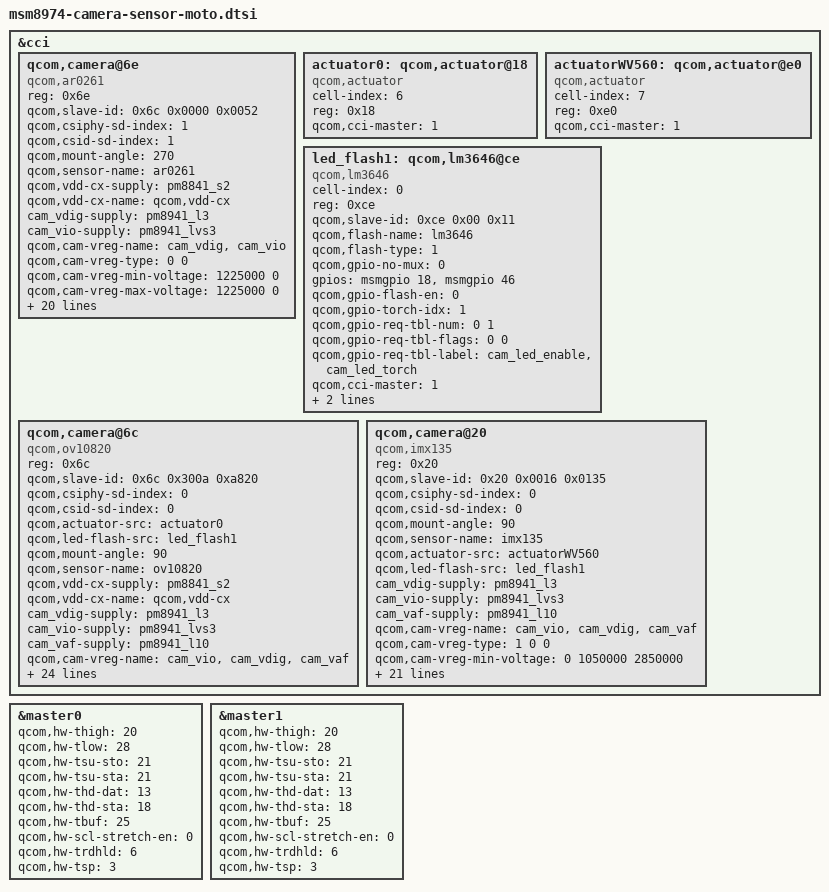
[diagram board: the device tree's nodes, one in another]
/*
 * Copyright (c) 2012-2013, The Linux Foundation. All rights reserved.
 *
 * This program is free software; you can redistribute it and/or modify
 * it under the terms of the GNU General Public License version 2 and
 * only version 2 as published by the Free Software Foundation.
 *
 * This program is distributed in the hope that it will be useful,
 * but WITHOUT ANY WARRANTY; without even the implied warranty of
 * MERCHANTABILITY or FITNESS FOR A PARTICULAR PURPOSE.  See the
 * GNU General Public License for more details.
 */

&cci {

	qcom,camera@6e {
		compatible = "qcom,ar0261";
		reg = <0x6e>;
		qcom,slave-id = <0x6c 0x0000 0x0052>;
		qcom,csiphy-sd-index = <1>;
		qcom,csid-sd-index = <1>;
		qcom,mount-angle = <270>;
		qcom,sensor-name = "ar0261";
		qcom,vdd-cx-supply = <&pm8841_s2>;
		qcom,vdd-cx-name = "qcom,vdd-cx";
		cam_vdig-supply = <&pm8941_l3>;
		cam_vio-supply = <&pm8941_lvs3>;
		qcom,cam-vreg-name = "cam_vdig", "cam_vio";
		qcom,cam-vreg-type = <0 0>;
		qcom,cam-vreg-min-voltage = <1225000 0>;
		qcom,cam-vreg-max-voltage = <1225000 0>;
		qcom,cam-vreg-op-mode = <105000 0>;
		qcom,gpio-no-mux = <0>;
		gpios = <&msmgpio 17 0>,
			<&msmgpio 103 0>,
			<&msmgpio 96 0>,
			<&msmgpio 7 0>;
		qcom,gpio-reset = <1>;
		qcom,gpio-standby = <2>;
		qcom,gpio-pwren = <3>;
		qcom,gpio-req-tbl-num = <0 1 2 3>;
		qcom,gpio-req-tbl-flags = <1 0 0 0>;
		qcom,gpio-req-tbl-label = "CAMIF_MCLK",
					  "CAM_RESET",
					  "CAM_AVDD",
					  "CAM_VDIG";
		qcom,gpio-set-tbl-num = <1 1>;
		qcom,gpio-set-tbl-flags = <0 2>;
		qcom,gpio-set-tbl-delay = <1000 4000>;
		qcom,csi-lane-assign = <0x4320>;
		qcom,csi-lane-mask = <0x07>;
		qcom,sensor-position = <1>;
		qcom,sensor-mode = <1>;
		qcom,sensor-type = <0>;
		qcom,cci-master = <1>;
		status = "ok";
	};

	actuator0: qcom,actuator@18 {
		cell-index = <6>;
		reg = <0x18>;
		compatible = "qcom,actuator";
		qcom,cci-master = <1>;
	};

	actuatorWV560: qcom,actuator@e0 {
		cell-index = <7>;
		reg = <0xe0>;
		compatible = "qcom,actuator";
		qcom,cci-master = <1>;
	};

	led_flash1: qcom,lm3646@ce {
		cell-index = <0>;
		reg = <0xce>;
		qcom,slave-id = <0xce 0x00 0x11>;
		compatible = "qcom,lm3646";
		qcom,flash-name = "lm3646";
		qcom,flash-type = <1>;
		qcom,gpio-no-mux = <0>;
		gpios = <&msmgpio 18 0>,
		        <&msmgpio 46 0>;
		qcom,gpio-flash-en = <0>;
		qcom,gpio-torch-idx = <1>;
		qcom,gpio-req-tbl-num = <0 1>;
		qcom,gpio-req-tbl-flags = <0 0>;
		qcom,gpio-req-tbl-label = "cam_led_enable",
			                  "cam_led_torch";
		qcom,cci-master = <1>;
		flash-en-support = <1>;
		flash-now-support = <0>;
	};

	qcom,camera@6c {
		compatible = "qcom,ov10820";
		reg = <0x6c>;
		qcom,slave-id = <0x6c 0x300a 0xa820>;
		qcom,csiphy-sd-index = <0>;
		qcom,csid-sd-index = <0>;
		qcom,actuator-src = <&actuator0>;
		qcom,led-flash-src = <&led_flash1>;
		qcom,mount-angle = <90>;
		qcom,sensor-name = "ov10820";
		qcom,vdd-cx-supply = <&pm8841_s2>;
		qcom,vdd-cx-name = "qcom,vdd-cx";
		cam_vdig-supply = <&pm8941_l3>;
		cam_vio-supply = <&pm8941_lvs3>;
		cam_vaf-supply = <&pm8941_l10>;
		qcom,cam-vreg-name = "cam_vio", "cam_vdig", "cam_vaf";
		qcom,cam-vreg-type = <0 0 0>;
		qcom,cam-vreg-min-voltage = <0 1225000 2850000>;
		qcom,cam-vreg-max-voltage = <0 1225000 2850000>;
		qcom,cam-vreg-op-mode = <0 105000 0>;
		qcom,gpio-no-mux = <0>;

		gpios = <&msmgpio 19 0>,
			<&msmgpio 89 0>,
			<&msmgpio 15 0>,
			<&pm8941_gpios 13 0>,
			<&pm8941_gpios 25 0>,
			<&pm8941_gpios 7  0>,
			<&msmgpio 91 0>;
		qcom,gpio-reset = <4>;
		qcom,gpio-standby = <1>;
		qcom,gpio-pwren = <3>;
		qcom,gpio-req-tbl-num = <0 1 2 3 4 5 6>;
		qcom,gpio-req-tbl-flags = <0 0 0 0 0 0 0>;
		qcom,gpio-req-tbl-label = "ANA_EN",
					  "PWDN_N",
					  "MCLK",
					  "DVDD_EN",
					  "RST_N",
					  "OV660_RST_N",
					  "DIG_EN";

		qcom,gpio-set-tbl-num = <1 1>;
		qcom,gpio-set-tbl-flags = <0 2>;
		qcom,gpio-set-tbl-delay = <1000 4000>;
		qcom,csi-lane-assign = <0x4320>;
		qcom,csi-lane-mask = <0x1f>;
		qcom,sensor-position = <0>;
		qcom,sensor-mode = <0>;
		qcom,sensor-type = <0>;
		qcom,cci-master = <1>;
		status = "ok";
	};

	qcom,camera@20 {
		compatible = "qcom,imx135";
		reg = <0x20>;
		qcom,slave-id = <0x20 0x0016 0x0135>;
		qcom,csiphy-sd-index = <0>;
		qcom,csid-sd-index = <0>;
		qcom,mount-angle = <90>;
		qcom,sensor-name = "imx135";
		qcom,actuator-src = <&actuatorWV560>;
		qcom,led-flash-src = <&led_flash1>;
		cam_vdig-supply = <&pm8941_l3>;
		cam_vio-supply = <&pm8941_lvs3>;
		cam_vaf-supply = <&pm8941_l10>;
		qcom,cam-vreg-name = "cam_vio", "cam_vdig", "cam_vaf";
		qcom,cam-vreg-type = <1 0 0>;
		qcom,cam-vreg-min-voltage = <0 1050000 2850000>;
		qcom,cam-vreg-max-voltage = <0 1225000 2850000>;
		qcom,cam-vreg-op-mode = <0 1050000 0>;
		qcom,gpio-no-mux = <0>;
		gpios = <&msmgpio 15 0>,
			<&msmgpio 19 0>,
			<&msmgpio 89 0>,
			<&pm8941_gpios 13 0>,
			<&pm8941_gpios 25 0>;
		qcom,gpio-reset = <4>;
		qcom,gpio-vana = <1>;
		qcom,gpio-vdig = <3>;
		qcom,gpio-req-tbl-num = <0 1 2 3 4>;
		qcom,gpio-req-tbl-flags = <0 0 1 0 0>;
		qcom,gpio-req-tbl-label = "MCLK",
					  "ANA_EN",
					  "EEPROM_WP",
					  "DVDD_EN",
					  "CAM_RESET";
		qcom,gpio-set-tbl-num = <1 1>;
		qcom,gpio-set-tbl-flags = <0 2>;
		qcom,gpio-set-tbl-delay = <1000 30000>;
		qcom,csi-lane-assign = <0x4320>;
		qcom,csi-lane-mask = <0x1f>;
		qcom,sensor-position = <0>;
		qcom,sensor-mode = <0>;
		qcom,sensor-type = <0>;
		qcom,cci-master = <1>;
		status = "ok";
	};
};

&master0 {
	qcom,hw-thigh = <20>;
	qcom,hw-tlow = <28>;
	qcom,hw-tsu-sto = <21>;
	qcom,hw-tsu-sta = <21>;
	qcom,hw-thd-dat = <13>;
	qcom,hw-thd-sta = <18>;
	qcom,hw-tbuf = <25>;
	qcom,hw-scl-stretch-en = <0>;
	qcom,hw-trdhld = <6>;
	qcom,hw-tsp = <3>;
	status = "ok";
};

&master1 {
	qcom,hw-thigh = <20>;
	qcom,hw-tlow = <28>;
	qcom,hw-tsu-sto = <21>;
	qcom,hw-tsu-sta = <21>;
	qcom,hw-thd-dat = <13>;
	qcom,hw-thd-sta = <18>;
	qcom,hw-tbuf = <25>;
	qcom,hw-scl-stretch-en = <0>;
	qcom,hw-trdhld = <6>;
	qcom,hw-tsp = <3>;
	status = "ok";
};
